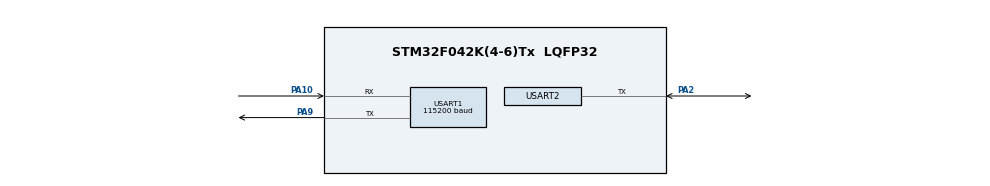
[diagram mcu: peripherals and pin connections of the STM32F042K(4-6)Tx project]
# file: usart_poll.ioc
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Mcu.Family=STM32F0
PA10.Mode=Asynchronous
USART1.BaudRate=115200
USART1.WordLength=WORDLENGTH_8B
Mcu.Name=STM32F042K(4-6)Tx
PA2.Signal=USART2_TX
Mcu.Package=LQFP32
ProjectManager.StackSize=0x400
USART1.VirtualMode-Asynchronous=VM_ASYNC
USART2.VirtualMode-Half_duplex(single_wire_mode)=VM_ASYNC
PA9.Mode=Asynchronous
PA10.Signal=USART1_RX
ProjectManager.HeapSize=0x200
USART2.WordLength=WORDLENGTH_8B
ProjectManager.TargetToolchain=SW4STM32
PA9.Signal=USART1_TX
PA2.Mode=Half_duplex(single_wire_mode)
board=usart_poll

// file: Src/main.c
/* USER CODE BEGIN Header */
/**
  ******************************************************************************
  * @file           : main.c
  * @brief          : Main program body
  ******************************************************************************
  * @attention
  *
  * <h2><center>&copy; Copyright (c) 2020 STMicroelectronics.
  * All rights reserved.</center></h2>
  *
  * This software component is licensed by ST under BSD 3-Clause license,
  * the "License"; You may not use this file except in compliance with the
  * License. You may obtain a copy of the License at:
  *                        opensource.org/licenses/BSD-3-Clause
  *
  ******************************************************************************
  */
/* USER CODE END Header */

#include "main.h"

/* USER CODE BEGIN Includes */
#include <assert.h>
/* USER CODE END Includes */

UART_HandleTypeDef huart1;
UART_HandleTypeDef huart2;

/* USER CODE BEGIN PV */
/* Private variables ---------------------------------------------------------*/

/* USER CODE END PV */

void SystemClock_Config(void);
static void MX_GPIO_Init(void);
static void MX_USART1_UART_Init(void);
static void MX_USART2_UART_Init(void);
/* USER CODE BEGIN PFP */
/* Private function prototypes -----------------------------------------------*/

/* USER CODE END PFP */

int main(void)
{

  /* MCU Configuration--------------------------------------------------------*/

  /* Reset of all peripherals, Initializes the Flash interface and the Systick. */
  HAL_Init();

  /* Configure the system clock */
  SystemClock_Config();

  /* Initialize all configured peripherals */
  MX_GPIO_Init();
  MX_USART1_UART_Init();
  MX_USART2_UART_Init();
  /* USER CODE BEGIN 2 */

  HAL_StatusTypeDef status;
  uint8_t ch = 0;
  int checksCount = 0;
  const int maxChecksCount = 100;

  while (checksCount < maxChecksCount) {
      status = HAL_UART_Receive(&huart1, &ch, 1, 5000);

      assert(status == HAL_OK || HAL_TIMEOUT);

      if (status == HAL_OK) {
          assert(HAL_OK == HAL_UART_Transmit(&huart1, &ch, 1, 5000));
          assert(HAL_OK == HAL_UART_Transmit(&huart2, &ch, 1, 5000));
          checksCount++;
      }
  }

  /* USER CODE END 2 */

  /* Infinite loop */
  while (1)
  {

  }
}

void SystemClock_Config(void)
{
  RCC_OscInitTypeDef RCC_OscInitStruct = {0};
  RCC_ClkInitTypeDef RCC_ClkInitStruct = {0};
  RCC_PeriphCLKInitTypeDef PeriphClkInit = {0};

  /** Initializes the CPU, AHB and APB busses clocks
  */
  RCC_OscInitStruct.OscillatorType = RCC_OSCILLATORTYPE_HSI;
  RCC_OscInitStruct.HSIState = RCC_HSI_ON;
  RCC_OscInitStruct.HSICalibrationValue = RCC_HSICALIBRATION_DEFAULT;
  RCC_OscInitStruct.PLL.PLLState = RCC_PLL_NONE;
  if (HAL_RCC_OscConfig(&RCC_OscInitStruct) != HAL_OK)
  {
    Error_Handler();
  }
  /** Initializes the CPU, AHB and APB busses clocks
  */
  RCC_ClkInitStruct.ClockType = RCC_CLOCKTYPE_HCLK|RCC_CLOCKTYPE_SYSCLK
                              |RCC_CLOCKTYPE_PCLK1;
  RCC_ClkInitStruct.SYSCLKSource = RCC_SYSCLKSOURCE_HSI;
  RCC_ClkInitStruct.AHBCLKDivider = RCC_SYSCLK_DIV1;
  RCC_ClkInitStruct.APB1CLKDivider = RCC_HCLK_DIV1;

  if (HAL_RCC_ClockConfig(&RCC_ClkInitStruct, FLASH_LATENCY_0) != HAL_OK)
  {
    Error_Handler();
  }
  PeriphClkInit.PeriphClockSelection = RCC_PERIPHCLK_USART1;
  PeriphClkInit.Usart1ClockSelection = RCC_USART1CLKSOURCE_PCLK1;
  if (HAL_RCCEx_PeriphCLKConfig(&PeriphClkInit) != HAL_OK)
  {
    Error_Handler();
  }
}

static void MX_USART1_UART_Init(void)
{

  huart1.Instance = USART1;
  huart1.Init.BaudRate = 115200;
  huart1.Init.WordLength = UART_WORDLENGTH_8B;
  huart1.Init.StopBits = UART_STOPBITS_1;
  huart1.Init.Parity = UART_PARITY_NONE;
  huart1.Init.Mode = UART_MODE_TX_RX;
  huart1.Init.HwFlowCtl = UART_HWCONTROL_NONE;
  huart1.Init.OverSampling = UART_OVERSAMPLING_16;
  huart1.Init.OneBitSampling = UART_ONE_BIT_SAMPLE_DISABLE;
  huart1.AdvancedInit.AdvFeatureInit = UART_ADVFEATURE_NO_INIT;
  if (HAL_UART_Init(&huart1) != HAL_OK)
  {
    Error_Handler();
  }

}

static void MX_USART2_UART_Init(void)
{

  huart2.Instance = USART2;
  huart2.Init.BaudRate = 38400;
  huart2.Init.WordLength = UART_WORDLENGTH_8B;
  huart2.Init.StopBits = UART_STOPBITS_1;
  huart2.Init.Parity = UART_PARITY_NONE;
  huart2.Init.Mode = UART_MODE_TX_RX;
  huart2.Init.HwFlowCtl = UART_HWCONTROL_NONE;
  huart2.Init.OverSampling = UART_OVERSAMPLING_16;
  huart2.Init.OneBitSampling = UART_ONE_BIT_SAMPLE_DISABLE;
  huart2.AdvancedInit.AdvFeatureInit = UART_ADVFEATURE_NO_INIT;
  if (HAL_HalfDuplex_Init(&huart2) != HAL_OK)
  {
    Error_Handler();
  }

}

static void MX_GPIO_Init(void)
{

  /* GPIO Ports Clock Enable */
  __HAL_RCC_GPIOA_CLK_ENABLE();

}

void Error_Handler(void)
{
  while(1)
  {
  }
}

/************************ (C) COPYRIGHT STMicroelectronics *****END OF FILE****/
